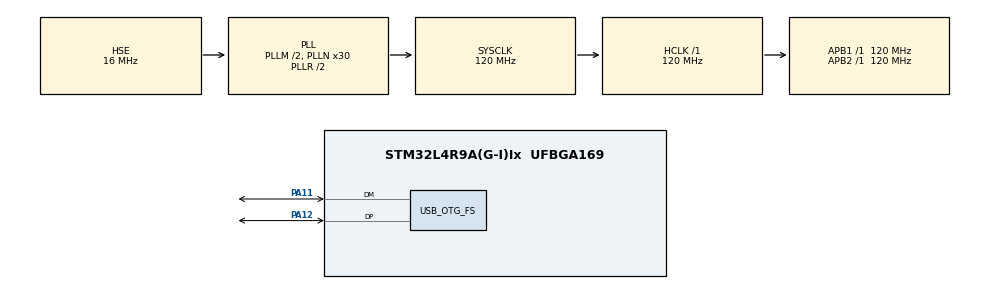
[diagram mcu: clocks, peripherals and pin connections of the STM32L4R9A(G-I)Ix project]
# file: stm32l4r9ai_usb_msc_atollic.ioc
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Mcu.Family=STM32L4
Mcu.Name=STM32L4R9A(G-I)Ix
Mcu.Package=UFBGA169
NVIC.OTG_FS_IRQn=true\:1\:0\:true\:false\:true\:false\:true
NVIC.PriorityGroup=NVIC_PRIORITYGROUP_4
OCTOSPI1.ChipSelectBoundary=0
OCTOSPI1.ChipSelectHighTime=2
OCTOSPI1.ClockPrescaler=2
OCTOSPI1.DelayHoldQuarterCycle=HAL_OSPI_DHQC_ENABLE
OCTOSPI1.DeviceSize=0x4000000
OCTOSPI1.FifoThreshold=4
OCTOSPI1.Mask=1
OCTOSPI1.MemoryType=HAL_OSPI_MEMTYPE_MACRONIX
OCTOSPI1.OperationType=HAL_OSPI_OPTYPE_COMMON_CFG
PA11.Mode=Device_Only
PA11.Signal=USB_OTG_FS_DM
PA12.Mode=Device_Only
PA12.Signal=USB_OTG_FS_DP
PH0-OSC_IN\ (PH0).Mode=HSE-External-Oscillator
PH0-OSC_IN\ (PH0).Signal=RCC_OSC_IN
PH1-OSC_OUT\ (PH1).Mode=HSE-External-Oscillator
PH1-OSC_OUT\ (PH1).Signal=RCC_OSC_OUT
ProjectManager.HeapSize=0x4000
ProjectManager.StackSize=0x800
ProjectManager.TargetToolchain=TrueSTUDIO
RCC.ADCFreq_Value=48000000
RCC.AHBFreq_Value=120000000
RCC.APB1Freq_Value=120000000
RCC.APB1TimFreq_Value=120000000
RCC.APB2Freq_Value=120000000
RCC.APB2TimFreq_Value=120000000
RCC.CortexFreq_Value=120000000
RCC.HCLKFreq_Value=120000000
RCC.HSE_VALUE=16000000
RCC.HSI48_VALUE=48000000
RCC.HSI_VALUE=16000000
RCC.LSE_VALUE=32768
RCC.MSI_VALUE=4000000
RCC.PLLM1=2
RCC.PLLM2=2
RCC.PLLN=30
RCC.PLLSAI1N=12
RCC.PLLSourceVirtual=RCC_PLLSOURCE_HSE
RCC.SYSCLKFreq_VALUE=120000000
RCC.SYSCLKSource=RCC_SYSCLKSOURCE_PLLCLK
RCC.USBFreq_Value=48000000
RCC.VCOOutputFreq_Value=240000000
RCC.VDD_VALUE=1.8
USB_DEVICE.CLASS_NAME_FS=MSC
USB_DEVICE.MSC_MEDIA_PACKET=4096
USB_DEVICE.VirtualMode=Msc
USB_DEVICE.VirtualModeFS=Msc_FS
USB_OTG_FS.VirtualMode=Device_Only
USB_OTG_FS.low_power_enable=DISABLE
VP_OCTOSPI1_VS_octo.Mode=octo_mode
VP_USB_DEVICE_VS_USB_DEVICE_MSC_FS.Mode=MSC_FS
board=custom

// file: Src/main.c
/* USER CODE BEGIN Header */
/**
  ******************************************************************************
  * @file           : main.c
  * @brief          : Main program body
  ******************************************************************************
  * @attention
  *
  * <h2><center>&copy; Copyright (c) 2019 STMicroelectronics.
  * All rights reserved.</center></h2>
  *
  * This software component is licensed by ST under Ultimate Liberty license
  * SLA0044, the "License"; You may not use this file except in compliance with
  * the License. You may obtain a copy of the License at:
  *                             www.st.com/SLA0044
  *
  ******************************************************************************
  */
/* USER CODE END Header */

#include "main.h"
#include "octospi.h"
#include "usb_device.h"
#include "gpio.h"

/* USER CODE BEGIN Includes */
#include "exflash.h"
/* USER CODE END Includes */

void SystemClock_Config(void);

int main(void)
{

  /* MCU Configuration--------------------------------------------------------*/

  /* Reset of all peripherals, Initializes the Flash interface and the Systick. */
  HAL_Init();

  /* Configure the system clock */
  SystemClock_Config();

  /* USER CODE BEGIN SysInit */
#if 1
  MX_GPIO_Init();
  MX_USB_DEVICE_Init();
#else
  /* USER CODE END SysInit */

  /* Initialize all configured peripherals */
  MX_GPIO_Init();
  MX_USB_DEVICE_Init();
  MX_OCTOSPI1_Init();
  /* USER CODE BEGIN 2 */
#endif
  BSP_OSPI_NOR_Init();
  static uint8_t pData[4096];
#if 0
  BSP_OSPI_NOR_Erase_Chip();
  BSP_OSPI_NOR_Erase_Block(0);
#endif
  /* USER CODE END 2 */

  /* Infinite loop */
  /* USER CODE BEGIN WHILE */
  while (1)
  {
    HAL_Delay(1000);
    /* USER CODE END WHILE */

  }
}

void SystemClock_Config(void)
{
  RCC_OscInitTypeDef RCC_OscInitStruct = {0};
  RCC_ClkInitTypeDef RCC_ClkInitStruct = {0};
  RCC_PeriphCLKInitTypeDef PeriphClkInit = {0};

  /** Configure the main internal regulator output voltage
  */
  if (HAL_PWREx_ControlVoltageScaling(PWR_REGULATOR_VOLTAGE_SCALE1_BOOST) != HAL_OK)
  {
    Error_Handler();
  }
  /** Initializes the CPU, AHB and APB busses clocks
  */
  RCC_OscInitStruct.OscillatorType = RCC_OSCILLATORTYPE_HSE;
  RCC_OscInitStruct.HSEState = RCC_HSE_ON;
  RCC_OscInitStruct.PLL.PLLState = RCC_PLL_ON;
  RCC_OscInitStruct.PLL.PLLSource = RCC_PLLSOURCE_HSE;
  RCC_OscInitStruct.PLL.PLLM = 2;
  RCC_OscInitStruct.PLL.PLLN = 30;
  RCC_OscInitStruct.PLL.PLLP = RCC_PLLP_DIV2;
  RCC_OscInitStruct.PLL.PLLQ = RCC_PLLQ_DIV2;
  RCC_OscInitStruct.PLL.PLLR = RCC_PLLR_DIV2;
  if (HAL_RCC_OscConfig(&RCC_OscInitStruct) != HAL_OK)
  {
    Error_Handler();
  }
  /** Initializes the CPU, AHB and APB busses clocks
  */
  RCC_ClkInitStruct.ClockType = RCC_CLOCKTYPE_HCLK|RCC_CLOCKTYPE_SYSCLK
                              |RCC_CLOCKTYPE_PCLK1|RCC_CLOCKTYPE_PCLK2;
  RCC_ClkInitStruct.SYSCLKSource = RCC_SYSCLKSOURCE_PLLCLK;
  RCC_ClkInitStruct.AHBCLKDivider = RCC_SYSCLK_DIV1;
  RCC_ClkInitStruct.APB1CLKDivider = RCC_HCLK_DIV1;
  RCC_ClkInitStruct.APB2CLKDivider = RCC_HCLK_DIV1;

  if (HAL_RCC_ClockConfig(&RCC_ClkInitStruct, FLASH_LATENCY_5) != HAL_OK)
  {
    Error_Handler();
  }
  PeriphClkInit.PeriphClockSelection = RCC_PERIPHCLK_USB|RCC_PERIPHCLK_OSPI;
  PeriphClkInit.OspiClockSelection = RCC_OSPICLKSOURCE_SYSCLK;
  PeriphClkInit.UsbClockSelection = RCC_USBCLKSOURCE_PLLSAI1;
  PeriphClkInit.PLLSAI1.PLLSAI1Source = RCC_PLLSOURCE_HSE;
  PeriphClkInit.PLLSAI1.PLLSAI1M = 2;
  PeriphClkInit.PLLSAI1.PLLSAI1N = 12;
  PeriphClkInit.PLLSAI1.PLLSAI1P = RCC_PLLP_DIV2;
  PeriphClkInit.PLLSAI1.PLLSAI1Q = RCC_PLLQ_DIV2;
  PeriphClkInit.PLLSAI1.PLLSAI1R = RCC_PLLR_DIV2;
  PeriphClkInit.PLLSAI1.PLLSAI1ClockOut = RCC_PLLSAI1_48M2CLK;
  if (HAL_RCCEx_PeriphCLKConfig(&PeriphClkInit) != HAL_OK)
  {
    Error_Handler();
  }
}

void Error_Handler(void)
{
}

/************************ (C) COPYRIGHT STMicroelectronics *****END OF FILE****/
